VERSION "created by canmatrix"

NS_ :

BS_:

BU_:

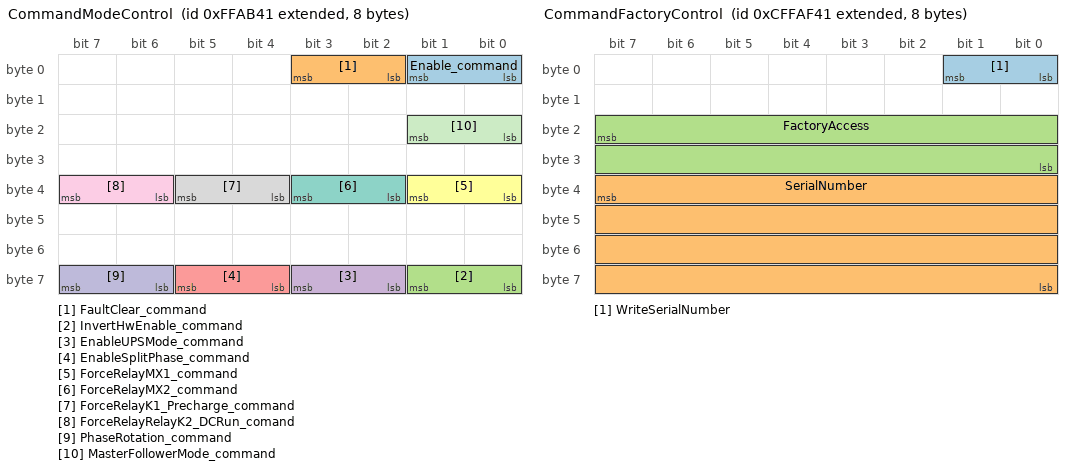
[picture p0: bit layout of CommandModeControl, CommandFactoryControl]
BO_ 2164239169 CommandModeControl: 8 Vector__XXX
 SG_ Enable_command : 1|2@0+ (1,0) [0.0|3.0] "" Vector__XXX
 SG_ FaultClear_command : 3|2@0+ (1,0) [0.0|3.0] "" Vector__XXX
 SG_ InvertHwEnable_command : 57|2@0+ (1,0) [0.0|3.0] "" Vector__XXX
 SG_ EnableUPSMode_command : 59|2@0+ (1,0) [0.0|3.0] "" Vector__XXX
 SG_ EnableSplitPhase_command : 61|2@0+ (1,0) [0.0|3.0] "" Vector__XXX
 SG_ ForceRelayMX1_command : 33|2@0+ (1,0) [0.0|3.0] "" Vector__XXX
 SG_ ForceRelayMX2_command : 35|2@0+ (1,0) [0.0|3.0] "" Vector__XXX
 SG_ ForceRelayK1_Precharge_command : 37|2@0+ (1,0) [0.0|3.0] "" Vector__XXX
 SG_ ForceRelayRelayK2_DCRun_comand : 39|2@0+ (1,0) [0.0|3.0] "" Vector__XXX
 SG_ PhaseRotation_command : 63|2@0+ (1,0) [0.0|3.0] "" Vector__XXX
 SG_ MasterFollowerMode_command : 17|2@0+ (1,0) [0.0|3.0] "" Vector__XXX

BO_ 2365566017 CommandPower: 8 Vector__XXX
 SG_ RealPower_command : 7|32@0- (1,0) [-2147483648.0|2147483647.0] "" Vector__XXX
 SG_ ReactivePower_command : 39|32@0- (1,0) [-2147483648.0|2147483647.0] "" Vector__XXX

BO_ 2365566529 CommandVF: 8 Vector__XXX
 SG_ Voltage_command : 7|16@0+ (0.1,0) [0.0|6553.5] "" Vector__XXX
 SG_ Frequency_command : 23|16@0+ (0.1,0) [0.0|6553.5] "" Vector__XXX

BO_ 2365573878 MasterMeasuredPower: 8 Vector__XXX
 SG_ RealPower_measured : 7|32@0- (1,0) [-2147483648.0|2147483647.0] "" Vector__XXX
 SG_ ReactivePower_measured : 39|32@0- (1,0) [-2147483648.0|2147483647.0] "" Vector__XXX

BO_ 2365566785 CommandFactoryControl: 8 Vector__XXX
 SG_ WriteSerialNumber : 1|2@0+ (1,0) [0.0|3.0] "" Vector__XXX
 SG_ SerialNumber : 39|32@0+ (1,0) [0.0|4294967295.0] "" Vector__XXX
 SG_ FactoryAccess : 23|16@0+ (1,0) [0.0|65535.0] "" Vector__XXX

BO_ 2365565505 CommandSetNVParam: 8 Vector__XXX
 SG_ CommandSetNVParam_MUX : 7|16@0- (1,0) [-32768.0|32767.0] "" Vector__XXX
 SG_ Dummy : 23|16@0+ (1,0) [0.0|65535.0] "" Vector__XXX
 SG_ VUnder50pct : 23|16@0+ (1,0) [0.0|65535.0] "" Vector__XXX
 SG_ V50to88pct : 39|16@0+ (1,0) [0.0|65535.0] "" Vector__XXX
 SG_ V110to120pct : 55|16@0+ (1,0) [0.0|65535.0] "" Vector__XXX
 SG_ VOver120 : 23|16@0+ (1,0) [0.0|65535.0] "" Vector__XXX
 SG_ FreqHi : 23|16@0+ (0.1,0) [0.0|6553.5] "" Vector__XXX
 SG_ FreqLo : 39|16@0+ (0.1,0) [0.0|6553.5] "" Vector__XXX
 SG_ FreqVeryLo : 55|16@0+ (0.1,0) [0.0|6553.5] "" Vector__XXX
 SG_ FreqVeryLo : 23|16@0+ (1,0) [0.0|65535.0] "" Vector__XXX
 SG_ FreqLo : 39|16@0+ (1,0) [0.0|65535.0] "" Vector__XXX
 SG_ FreqHi : 55|16@0+ (1,0) [0.0|65535.0] "" Vector__XXX
 SG_ NodeID : 23|8@0+ (1,0) [0.0|255.0] "" Vector__XXX
 SG_ SA_Mask : 31|8@0+ (1,0) [0.0|255.0] "" Vector__XXX
 SG_ Baudrate : 39|4@0+ (1,0) [0.0|15.0] "" Vector__XXX
 SG_ ThermalOverload : 17|2@0+ (1,0) [0.0|3.0] "" Vector__XXX
 SG_ MX1Open : 23|16@0+ (1,0) [0.0|65535.0] "" Vector__XXX
 SG_ MX1Close : 39|16@0+ (1,0) [0.0|65535.0] "" Vector__XXX
 SG_ MX2Open : 55|16@0+ (1,0) [0.0|65535.0] "" Vector__XXX
 SG_ MX2Close : 23|16@0+ (1,0) [0.0|65535.0] "" Vector__XXX
 SG_ K1Open : 39|16@0+ (1,0) [0.0|65535.0] "" Vector__XXX
 SG_ K1Close : 55|16@0+ (1,0) [0.0|65535.0] "" Vector__XXX
 SG_ K2Open : 23|16@0+ (1,0) [0.0|65535.0] "" Vector__XXX
 SG_ K2Close : 39|16@0+ (1,0) [0.0|65535.0] "" Vector__XXX

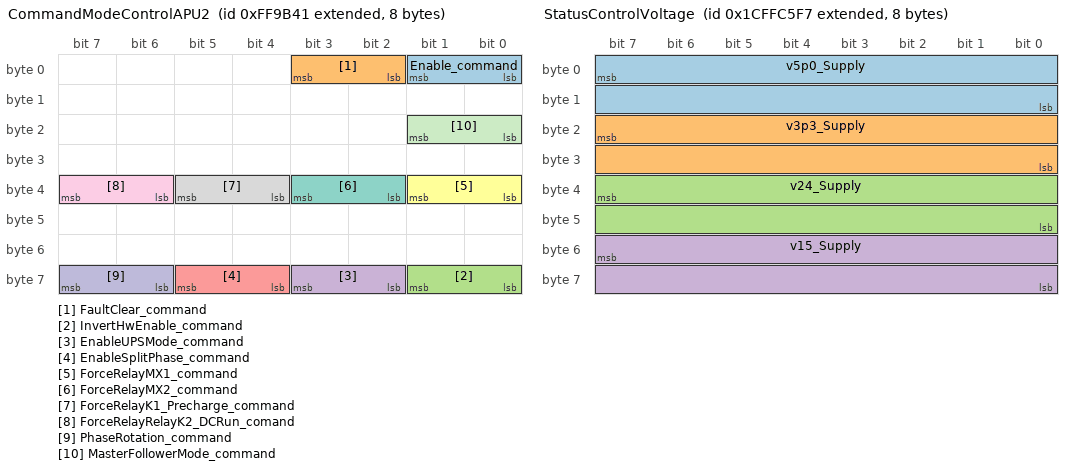
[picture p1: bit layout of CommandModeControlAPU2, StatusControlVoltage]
BO_ 2164235073 CommandModeControlAPU2: 8 Vector__XXX
 SG_ Enable_command : 1|2@0+ (1,0) [0.0|3.0] "" Vector__XXX
 SG_ FaultClear_command : 3|2@0+ (1,0) [0.0|3.0] "" Vector__XXX
 SG_ InvertHwEnable_command : 57|2@0+ (1,0) [0.0|3.0] "" Vector__XXX
 SG_ EnableUPSMode_command : 59|2@0+ (1,0) [0.0|3.0] "" Vector__XXX
 SG_ EnableSplitPhase_command : 61|2@0+ (1,0) [0.0|3.0] "" Vector__XXX
 SG_ ForceRelayMX1_command : 33|2@0+ (1,0) [0.0|3.0] "" Vector__XXX
 SG_ ForceRelayMX2_command : 35|2@0+ (1,0) [0.0|3.0] "" Vector__XXX
 SG_ ForceRelayK1_Precharge_command : 37|2@0+ (1,0) [0.0|3.0] "" Vector__XXX
 SG_ ForceRelayRelayK2_DCRun_comand : 39|2@0+ (1,0) [0.0|3.0] "" Vector__XXX
 SG_ PhaseRotation_command : 63|2@0+ (1,0) [0.0|3.0] "" Vector__XXX
 SG_ MasterFollowerMode_command : 17|2@0+ (1,0) [0.0|3.0] "" Vector__XXX

BO_ 2365561921 CommandPowerAPU2: 8 Vector__XXX
 SG_ RealPower_command : 7|32@0- (1,0) [-2147483648.0|2147483647.0] "" Vector__XXX
 SG_ ReactivePower_command : 39|32@0- (1,0) [-2147483648.0|2147483647.0] "" Vector__XXX

BO_ 2365562433 CommandVFAPU2: 8 Vector__XXX
 SG_ Voltage_command : 7|16@0+ (0.1,0) [0.0|6553.5] "" Vector__XXX
 SG_ Frequency_command : 23|16@0+ (0.1,0) [0.0|6553.5] "" Vector__XXX

BO_ 2365573879 MasterMeasuredPowerAPU2: 8 Vector__XXX
 SG_ RealPower_measured : 7|32@0- (1,0) [-2147483648.0|2147483647.0] "" Vector__XXX
 SG_ ReactivePower_measured : 39|32@0- (1,0) [-2147483648.0|2147483647.0] "" Vector__XXX

BO_ 2365573879 StatusMeasuredPower: 8 Vector__XXX
 SG_ RealPower_measured : 7|32@0- (1,0) [-2147483648.0|2147483647.0] "" Vector__XXX
 SG_ ReactivePower_measured : 39|32@0- (1,0) [-2147483648.0|2147483647.0] "" Vector__XXX

BO_ 2566898935 StatusCommandedPower: 8 Vector__XXX
 SG_ RealPower_echo : 7|32@0- (1,0) [-2147483648.0|2147483647.0] "" Vector__XXX
 SG_ ReactivePower_echo : 39|32@0- (1,0) [-2147483648.0|2147483647.0] "" Vector__XXX

BO_ 2365572087 StatusBits: 8 Vector__XXX
 SG_ State_status : 3|4@0+ (1,0) [0.0|15.0] "" Vector__XXX
 SG_ MX2Permissive_status : 19|2@0+ (1,0) [0.0|3.0] "" Vector__XXX
 SG_ PowerAvailAC_status : 11|2@0+ (1,0) [0.0|3.0] "" Vector__XXX
 SG_ PowerAvailDC_status : 13|2@0+ (1,0) [0.0|3.0] "" Vector__XXX
 SG_ PowerCircuitEnabled_status : 15|2@0+ (1,0) [0.0|3.0] "" Vector__XXX
 SG_ HardwareEnable_status : 9|2@0+ (1,0) [0.0|3.0] "" Vector__XXX
 SG_ Enable_echo : 5|2@0+ (1,0) [0.0|3.0] "" Vector__XXX
 SG_ FaultClr_echo : 7|2@0+ (1,0) [0.0|3.0] "" Vector__XXX
 SG_ MessageValidModeControl_status : 25|2@0+ (1,0) [0.0|3.0] "" Vector__XXX
 SG_ MX1Permissive_status : 17|2@0+ (1,0) [0.0|3.0] "" Vector__XXX
 SG_ K2DCRunPermissive_status : 23|2@0+ (1,0) [0.0|3.0] "" Vector__XXX
 SG_ K1PrechargePermissive_status : 21|2@0+ (1,0) [0.0|3.0] "" Vector__XXX
 SG_ MessageValidPowerCMD_status : 27|2@0+ (1,0) [0.0|3.0] "" Vector__XXX
 SG_ MessageValidVF_status : 29|2@0+ (1,0) [0.0|3.0] "" Vector__XXX
 SG_ CANbus_status : 31|2@0+ (1,0) [0.0|3.0] "" Vector__XXX
 SG_ EnableUPSMode_echo : 33|2@0+ (1,0) [0.0|3.0] "" Vector__XXX
 SG_ EnableSplitPhase_echo : 35|2@0+ (1,0) [0.0|3.0] "" Vector__XXX
 SG_ PhaseRotation_status : 37|2@0+ (1,0) [0.0|3.0] "" Vector__XXX
 SG_ LineVoltageDetected_status : 39|2@0+ (1,0) [0.0|3.0] "" Vector__XXX
 SG_ PhaseRotation_echo : 41|2@0+ (1,0) [0.0|3.0] "" Vector__XXX

BO_ 2634008055 StatusControlVoltage: 8 Vector__XXX
 SG_ v5p0_Supply : 7|16@0- (0.01,0) [-327.68|327.67] "" Vector__XXX
 SG_ v3p3_Supply : 23|16@0- (0.01,0) [-327.68|327.67] "" Vector__XXX
 SG_ v24_Supply : 39|16@0- (0.01,0) [-327.68|327.67] "" Vector__XXX
 SG_ v15_Supply : 55|16@0- (0.01,0) [-327.68|327.67] "" Vector__XXX

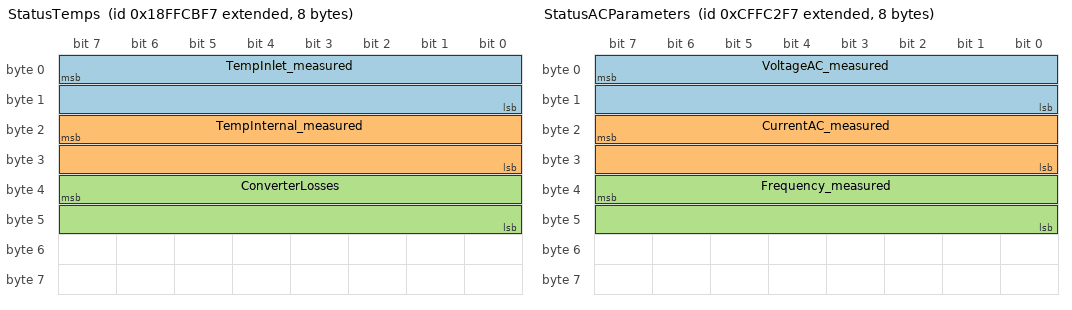
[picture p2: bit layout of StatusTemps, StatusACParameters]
BO_ 2566900727 StatusTemps: 8 Vector__XXX
 SG_ TempInlet_measured : 7|16@0- (0.1,0) [-3276.8|3276.7000000000003] "" Vector__XXX
 SG_ TempInternal_measured : 23|16@0- (0.1,0) [-3276.8|3276.7000000000003] "" Vector__XXX
 SG_ ConverterLosses : 39|16@0+ (1,0) [0.0|65535.0] "" Vector__XXX

BO_ 2365573367 StatusFaults: 8 Vector__XXX
 SG_ BridgeAVoltageOk_status : 59|1@0+ (1,0) [0.0|1.0] "" Vector__XXX
 SG_ OvercurrentAC_status : 3|2@0+ (1,0) [0.0|3.0] "" Vector__XXX
 SG_ BridgeBVoltageOk_status : 43|1@0+ (1,0) [0.0|1.0] "" Vector__XXX
 SG_ OvervoltageDC_status : 9|2@0+ (1,0) [0.0|3.0] "" Vector__XXX
 SG_ OvertempPowerDevice_status : 15|2@0+ (1,0) [0.0|3.0] "" Vector__XXX
 SG_ OvertempInternal_status : 13|2@0+ (1,0) [0.0|3.0] "" Vector__XXX
 SG_ LossValidControlMessage_status : 23|4@0+ (1,0) [0.0|15.0] "" Vector__XXX
 SG_ UndervoltageDC_status : 11|2@0+ (1,0) [0.0|3.0] "" Vector__XXX
 SG_ ControlHardwareFail_status : 19|4@0+ (1,0) [0.0|15.0] "" Vector__XXX
 SG_ OvercurrentDC_status : 7|2@0+ (1,0) [0.0|3.0] "" Vector__XXX
 SG_ GeneralFault_status : 1|2@0+ (1,0) [0.0|3.0] "" Vector__XXX
 SG_ LossOfAC_status : 5|2@0+ (1,0) [0.0|3.0] "" Vector__XXX
 SG_ EStopShutdown_status : 25|2@0+ (1,0) [0.0|3.0] "" Vector__XXX
 SG_ BridgeAFault_status : 58|3@0+ (1,0) [0.0|7.0] "" Vector__XXX
 SG_ BridgeBFault_status : 42|3@0+ (1,0) [0.0|7.0] "" Vector__XXX
 SG_ IllegalTransition_status : 27|2@0+ (1,0) [0.0|3.0] "" Vector__XXX
 SG_ InvalidEEHeader_status : 29|2@0+ (1,0) [0.0|3.0] "" Vector__XXX
 SG_ InvalidEESection_status : 31|2@0+ (1,0) [0.0|3.0] "" Vector__XXX
 SG_ ThermalOverload : 33|2@0+ (1,0) [0.0|3.0] "" Vector__XXX

BO_ 2365571831 StatusACParameters: 8 Vector__XXX
 SG_ VoltageAC_measured : 7|16@0- (0.1,0) [-3276.8|3276.7000000000003] "" Vector__XXX
 SG_ CurrentAC_measured : 23|16@0- (1,0) [-32768.0|32767.0] "" Vector__XXX
 SG_ Frequency_measured : 39|16@0- (0.1,0) [-3276.8|3276.7000000000003] "" Vector__XXX

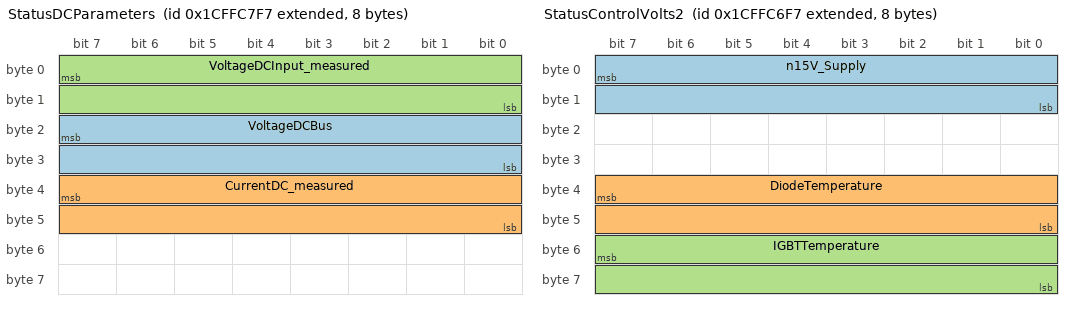
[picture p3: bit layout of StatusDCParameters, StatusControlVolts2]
BO_ 2634008567 StatusDCParameters: 8 Vector__XXX
 SG_ VoltageDCBus : 23|16@0- (1,0) [-32768.0|32767.0] "" Vector__XXX
 SG_ CurrentDC_measured : 39|16@0- (1,0) [-32768.0|32767.0] "" Vector__XXX
 SG_ VoltageDCInput_measured : 7|16@0- (1,0) [-32768.0|32767.0] "" Vector__XXX

BO_ 2634008311 StatusControlVolts2: 8 Vector__XXX
 SG_ n15V_Supply : 7|16@0- (0.01,0) [-327.68|327.67] "" Vector__XXX
 SG_ DiodeTemperature : 39|16@0+ (1,0) [0.0|65535.0] "" Vector__XXX
 SG_ IGBTTemperature : 55|16@0+ (1,0) [0.0|65535.0] "" Vector__XXX

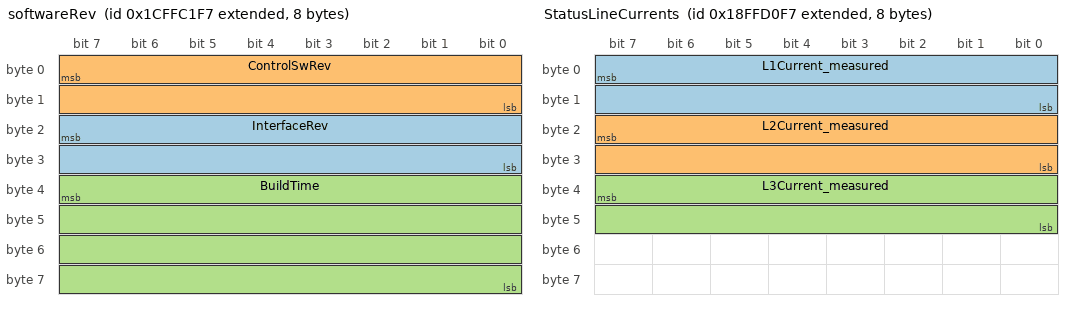
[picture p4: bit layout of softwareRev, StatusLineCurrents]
BO_ 2634007031 softwareRev: 8 Vector__XXX
 SG_ InterfaceRev : 23|16@0+ (0.01,0) [0.0|655.35] "" Vector__XXX
 SG_ ControlSwRev : 7|16@0+ (0.01,0) [0.0|655.35] "" Vector__XXX
 SG_ BuildTime : 39|32@0+ (1,0) [0.0|4294967295.0] "" Vector__XXX

BO_ 2566900215 StatusCommandVF: 8 Vector__XXX
 SG_ Voltage_echo : 7|16@0+ (0.1,0) [0.0|6553.5] "" Vector__XXX
 SG_ Frequency_echo : 23|16@0+ (0.1,0) [0.0|6553.5] "" Vector__XXX

BO_ 2634009847 serialNumber: 8 Vector__XXX
 SG_ SerialNumber : 7|32@0+ (1,0) [0.0|4294967295.0] "" Vector__XXX

BO_ 2634010103 softwareRevHash: 8 Vector__XXX
 SG_ Hash : 7|28@0+ (1,0) [0.0|268435455.0] "" Vector__XXX

BO_ 2634000887 StatusNVParam: 8 Vector__XXX
 SG_ StatusNVParam_MUX : 7|16@0- (1,0) [-32768.0|32767.0] "" Vector__XXX
 SG_ Dummy : 23|16@0+ (1,0) [0.0|65535.0] "" Vector__XXX
 SG_ VUnder50pct : 23|16@0+ (1,0) [0.0|65535.0] "" Vector__XXX
 SG_ V50to88pct : 39|16@0+ (1,0) [0.0|65535.0] "" Vector__XXX
 SG_ V110to120pct : 55|16@0+ (1,0) [0.0|65535.0] "" Vector__XXX
 SG_ VOver120 : 23|16@0+ (1,0) [0.0|65535.0] "" Vector__XXX
 SG_ FreqHi : 23|16@0+ (0.1,0) [0.0|6553.5] "" Vector__XXX
 SG_ FreqLo : 39|16@0+ (0.1,0) [0.0|6553.5] "" Vector__XXX
 SG_ FreqVeryLo : 55|16@0+ (0.1,0) [0.0|6553.5] "" Vector__XXX
 SG_ FreqVeryLo : 23|16@0+ (1,0) [0.0|65535.0] "" Vector__XXX
 SG_ FreqLo : 39|16@0+ (1,0) [0.0|65535.0] "" Vector__XXX
 SG_ FreqHi : 55|16@0+ (1,0) [0.0|65535.0] "" Vector__XXX
 SG_ StatusNodeID : 23|8@0+ (1,0) [0.0|255.0] "" Vector__XXX
 SG_ StatusSA_Mask : 31|8@0+ (1,0) [0.0|255.0] "" Vector__XXX
 SG_ StatusBaudrate : 39|4@0+ (1,0) [0.0|15.0] "" Vector__XXX
 SG_ StatusThermalOverload : 17|2@0+ (1,0) [0.0|3.0] "" Vector__XXX
 SG_ StatusMX1Open : 23|16@0+ (1,0) [0.0|65535.0] "" Vector__XXX
 SG_ StatusMX1Close : 39|16@0+ (1,0) [0.0|65535.0] "" Vector__XXX
 SG_ StatusMX2Open : 55|16@0+ (1,0) [0.0|65535.0] "" Vector__XXX
 SG_ StatusMX2Close : 23|16@0+ (1,0) [0.0|65535.0] "" Vector__XXX
 SG_ StatusK1Open : 39|16@0+ (1,0) [0.0|65535.0] "" Vector__XXX
 SG_ StatusK1Close : 55|16@0+ (1,0) [0.0|65535.0] "" Vector__XXX
 SG_ StatusK2Open : 23|16@0+ (1,0) [0.0|65535.0] "" Vector__XXX
 SG_ StatusK2Close : 39|16@0+ (1,0) [0.0|65535.0] "" Vector__XXX

BO_ 2566902007 StatusLineCurrents: 8 Vector__XXX
 SG_ L1Current_measured : 7|16@0+ (1,0) [0.0|65535.0] "" Vector__XXX
 SG_ L2Current_measured : 23|16@0+ (1,0) [0.0|65535.0] "" Vector__XXX
 SG_ L3Current_measured : 39|16@0+ (1,0) [0.0|65535.0] "" Vector__XXX

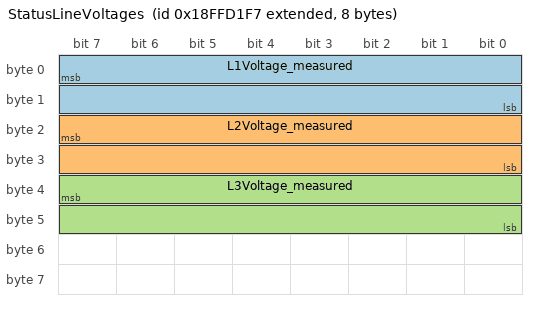
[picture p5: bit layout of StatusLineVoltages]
BO_ 2566902263 StatusLineVoltages: 8 Vector__XXX
 SG_ L1Voltage_measured : 7|16@0+ (0.1,0) [0.0|6553.5] "" Vector__XXX
 SG_ L2Voltage_measured : 23|16@0+ (0.1,0) [0.0|6553.5] "" Vector__XXX
 SG_ L3Voltage_measured : 39|16@0+ (0.1,0) [0.0|6553.5] "" Vector__XXX
